# LPC18xx register map
File version: 0.23
CPU: CM3 r0p0, little endian, no MPU, no FPU, 3 interrupt priority bits
Registers are 32-bit, read-write, reset 0x0 unless marked. A register's access mark holds for its fields unless they carry their own. Offsets are from the block's base; [hi:lo] are bit positions; <NAME> marks a mode.

## ETHERNET (part 1 of 2)
Base 0x40010000
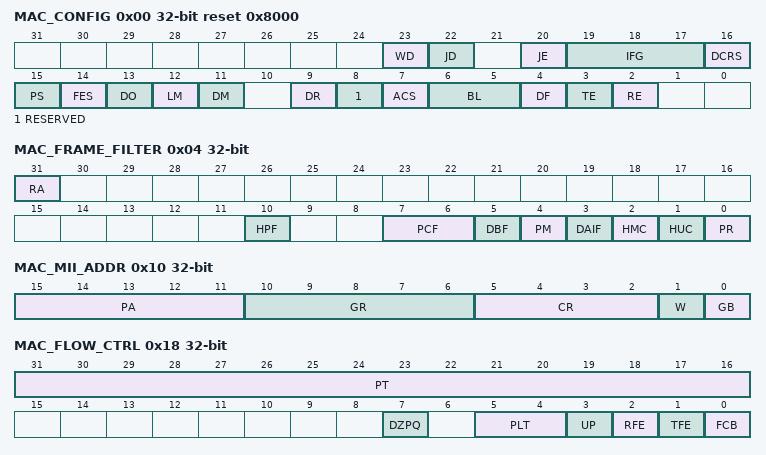
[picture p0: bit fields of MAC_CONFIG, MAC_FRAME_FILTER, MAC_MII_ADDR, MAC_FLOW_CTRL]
0x00 MAC_CONFIG reset 0x8000 — MAC configuration register
  [23] WD — Watchdog Disable When this bit is set, the MAC disables the watchdog timer on the receiver, and can receive frames of up to 16,384 bytes. When this bit is reset, the MAC allows no more than 2,048 bytes (10,240 if JE is set high) of the frame being received and cuts off any bytes received after that.
  [22] JD — Jabber Disable When this bit is set, the MAC disables the jabber timer on the transmitter, and can transfer frames of up to 16,384 bytes. When this bit is reset, the MAC cuts off the transmitter if the application sends out more than 2,048 bytes of data (10,240 if JE is set high) during transmission.
  [20] JE — Jumbo Frame Enable When this bit is set, MAC allows Jumbo frames of 9,018 bytes (9,022 bytes for VLAN tagged frames) without reporting a giant frame error in the receive frame status.
  [19:17] IFG — Inter-frame gap These bits control the minimum IFG between frames during transmission. 000 = 96 bit times 001 = 88 bit times 010 = 80 bit times ... 000 = 40 bit times Note that in Half-Duplex mode, the minimum IFG can be configured for 64 bit times (IFG = 100) only. Lower values are not considered
  [16] DCRS — Disable carrier sense during transmission When set high, this bit makes the MAC transmitter ignore the MII CRS signal during frame transmission in Half-Duplex mode. This request results in no errors generated due to Loss of Carrier or No Carrier during such transmission. When this bit is low, the MAC transmitter generates such errors due to Carrier Sense and will even abort the transmissions.
  [15] PS — Port select 1 = MII (100 Mbp) - this is the only allowed value.
  [14] FES — Speed Indicates the speed in Fast Ethernet (MII) mode: 0 = 10 Mbps 1 = 100 Mbps
  [13] DO — Disable Receive Own When this bit is set, the MAC disables the reception of frames in Half-Duplex mode. When this bit is reset, the MAC receives all packets that are given by the PHY while transmitting. This bit is not applicable if the MAC is operating in Full-Duplex mode.
  [12] LM — Loopback Mode When this bit is set, the MAC operates in loopback mode at MII. The MII Receive clock input is required for the loopback to work properly, as the Transmit clock is not looped-back internally.
  [11] DM — Duplex Mode When this bit is set, the MAC operates in a Full-Duplex mode where it can transmit and receive simultaneously.
  [9] DR — Disable Retry When this bit is set, the MAC will attempt only 1 transmission. When a collision occurs on the MII, the MAC will ignore the current frame transmission and report a Frame Abort with excessive collision error in the transmit frame status. When this bit is reset, the MAC will attempt retries based on the settings of BL. This bit is applicable only to Half-Duplex mode and is reserved (RO with default value) in Full- Duplex-only configuration.
  [8] RESERVED — Link Up/Down Indicates whether the link is up or down during the transmission of configuration in SMII interface: 0 = Link down 1 = Link up
  [7] ACS — Automatic Pad/CRC Stripping When this bit is set, the MAC strips the Pad/FCS field on incoming frames only if the length's field value is less than or equal to 1,500 bytes. All received frames with length field greater than or equal to 1,501 bytes are passed to the application without stripping the Pad/FCS field. When this bit is reset, the MAC will pass all incoming frames to the Host unmodified.
  [6:5] BL — Back-Off Limit The Back-Off limit determines the random integer number (r) of slot time delays (4,096 bit times for 1000 Mbps and 512 bit times for 10/100 Mbps) the MAC waits before rescheduling a transmission attempt during retries after a collision. This bit is applicable only to Half-Duplex mode and is reserved (RO) in Full-Duplex-only configuration. 00: k = min (n, 10) 01: k = min (n, 8) 10: k = min (n, 4) 11: k = min (n, 1) where n = retransmission attempt. The random integer r takes the value in the range 0 <= r <= 2k.
  [4] DF — Deferral Check When this bit is set, the deferral check function is enabled in the MAC. The MAC will issue a Frame Abort status, along with the excessive deferral error bit set in the transmit frame status when the transmit state machine is deferred for more than 24,288 bit times in 10/100-Mbps mode. If the Core is configured for 1000 Mbps operation, or if the Jumbo frame mode is enabled in 10/100-Mbps mode, the threshold for deferral is 155,680 bits times. Deferral begins when the transmitter is ready to transmit, but is prevented because of an active CRS (carrier sense) signal on the MII. Defer time is not cumulative. If the transmitter defers for 10,000 bit times, then transmits, collides, backs off, and then has to defer again after completion of back-off, the deferral timer resets to 0 and restarts. When this bit is reset, the deferral check function is disabled and the MAC defers until the CRS signal goes inactive. This bit is applicable only in Half-Duplex mode and is reserved (RO) in Full-Duplex-only configuration.
  [3] TE — Transmitter Enable When this bit is set, the transmit state machine of the MAC is enabled for transmission on the MII. When this bit is reset, the MAC transmit state machine is disabled after the completion of the transmission of the current frame, and will not transmit any further frames.
  [2] RE — Receiver enable When this bit is set, the receiver state machine of the MAC is enabled for receiving frames from the MII. When this bit is reset, the MAC receive state machine is disabled after the completion of the reception of the current frame, and will not receive any further frames from the MII.
0x04 MAC_FRAME_FILTER
  [31] RA — Receive all When this bit is set, the MAC Receiver module passes to the Application all frames received irrespective of whether they pass the address filter. The result of the SA/DA filtering is updated (pass or fail) in the corresponding bits in the Receive Status Word. When this bit is reset, the Receiver module passes to the Application only those frames that pass the SA/DA address filter.
  [10] HPF — Hash or perfect filter When set, this bit configures the address filter to pass a frame if it matches either the perfect filtering or the hash filtering as set by HMC or HUC bits. When low and if the HUC/HMC bit is set, the frame is passed only if it matches the Hash filter.
  [7:6] PCF — Pass Control Frames These bits control the forwarding of all control frames (including unicast and multicast PAUSE frames). Note that the processing of PAUSE control frames depends only on RFE of the Flow Control Register. 00 = MAC filters all control frames from reaching the application. 01 = MAC forwards all control frames except PAUSE control frames to application even if they fail the Address filter. 10 = MAC forwards all control frames to application even if they fail the Address Filter. 11 = MAC forwards control frames that pass the Address Filter.
  [5] DBF — Disable Broadcast Frames When this bit is set, the AFM module filters all incoming broadcast frames. When this bit is reset, the AFM module passes all received broadcast frames.
  [4] PM — Pass All Multicast When set, this bit indicates that all received frames with a multicast destination address (first bit in the destination address field is '1') are passed. When reset, filtering of multicast frame depends on HMC bit.
  [3] DAIF — DA Inverse Filtering When this bit is set, the Address Check block operates in inverse filtering mode for the DA address comparison for both unicast and multicast frames. When reset, normal filtering of frames is performed.
  [2] HMC — Hash Multicast When set, MAC performs destination address filtering of received multicast frames according to the hash table. When reset, the MAC performs a perfect destination address filtering for multicast frames, that is, it compares the DA field with the values programmed in DA registers.
  [1] HUC — Hash Unicast When set, MAC performs destination address filtering of unicast frames according to the hash table. When reset, the MAC performs a perfect destination address filtering for unicast frames, that is, it compares the DA field with the values programmed in DA registers.
  [0] PR — Promiscuous Mode When this bit is set, the Address Filter module passes all incoming frames regardless of its destination or source address. The SA/DA Filter Fails status bits of the Receive Status Word will always be cleared when PR is set.
0x08 MAC_HASHTABLE_HIGH — Hash table high register
  [31:0] HTH — Hash table high This field contains the upper 32 bits of Hash table.
0x0C MAC_HASHTABLE_LOW — Hash table low register
  [31:0] HTL — Hash table low This field contains the upper 32 bits of Hash table.
0x10 MAC_MII_ADDR — MII address register
  [15:11] PA — Physical layer address This field tells which of the 32 possible PHY devices are being accessed.
  [10:6] GR — MII register These bits select the desired MII register in the selected PHY device.
  [5:2] CR — CSR clock range The CSR Clock Range selection determines the frequency of the MDC clock. The suggested range of CLK_M3_ETHERNET frequency applicable for each value below (when Bit[5] = 0) ensures that the MDC clock is approximately between the frequency range 1.0 MHz - 2.5 MHz. When bit 5 is set, you can achieve MDC clock of frequency higher than the IEEE 802.3 specified frequency limit of 2.5 MHz and program a clock divider of lower value. For example, when CLK_M3_ETHERNET is of frequency 100 MHz and you program these bits as 1010, then the resultant MDC clock will be of 12.5 MHz which is outside the limit of IEEE 802.3 specified range. Program the values given below only if the interfacing chips supports faster MDC clocks. See Table 554 for bit values.
  [1] W — MII write When set, this bit tells the PHY that this will be a Write operation using the MII Data register. If this bit is not set, this will be a Read operation, placing the data in the MII Data register.
  [0] GB — MII busy This register field can be read by the application (Read), can be set to 1 by the application with a register write of 1 (Write Set), and is cleared to 0 by the core (Self Clear). The application cannot clear this type of field, and a register write of 0 to this bit has no effect on this field. This bit should read a logic 0 before writing to this register and the MAC_MII_DATA register. This bit must also be set to 0 during a Write to this register. During a PHY register access, this bit will be set to 1 by the Application to indicate that a Read or Write access is in progress. The MAC_MII_DATA register should be kept valid until this bit is cleared by the MAC during a PHY Write operation. The MAC_MII_DATA register is invalid until this bit is cleared by the MAC during a PHY Read operation. This register should not be written to until this bit is cleared.
0x14 MAC_MII_DATA — MII data register
  [15:0] GD — MII data This contains the 16-bit data value read from the PHY after a Management Read operation or the 16-bit data value to be written to the PHY before a Management Write operation.
0x18 MAC_FLOW_CTRL — Flow control register
  [31:16] PT — Pause time This field holds the value to be used in the Pause Time field in the transmit control frame. If the Pause Time bits is configured to be double-synchronized to the MII clock domain, then consecutive writes to this register should be performed only after at least 4 clock cycles in the destination clock domain.
  [7] DZPQ — Disable Zero-Quanta Pause When set, this bit disables the automatic generation of Zero-Quanta Pause Control frames on the deassertion of the flow-control signal from the FIFO layer. When this bit is reset, normal operation with automatic Zero-Quanta Pause Control frame generation is enabled.
  [5:4] PLT — Pause Low Threshold This field configures the threshold of the PAUSE timer at which the input flow control is checked for automatic retransmission of PAUSE Frame. The threshold values should be always less than the Pause Time configured in Bits[31:16]. For example, if PT = 0x100 (256 slot-times), and PLT = 01, then a second PAUSE frame is automatically transmitted if the flow control signal is asserted at 228 (256 - 28) slot-times after the first PAUSE frame is transmitted.
  [3] UP — Unicast Pause Frame Detect When this bit is set, the MAC will detect the Pause frames with the station's unicast address specified in MAC Address0 High Register and MAC Address0 Low Register, in addition to the detecting Pause frames with the unique multicast address. When this bit is reset, the MAC will detect only a Pause frame with the unique multicast address specified in the 802.3x standard.
  [2] RFE — Receive Flow Control Enable When this bit is set, the MAC will decode the received Pause frame and disable its transmitter for a specified (Pause Time) time. When this bit is reset, the decode function of the Pause frame is disabled.
  [1] TFE — Transmit Flow Control Enable In Full-Duplex mode, when this bit is set, the MAC enables the flow control operation to transmit Pause frames. When this bit is reset, the flow control operation in the MAC is disabled, and the MAC will not transmit any Pause frames. In Half-Duplex mode, when this bit is set, the MAC enables the back-pressure operation. When this bit is reset, the backpressure feature is disabled.
  [0] FCB — Flow Control Busy/Backpressure Activate This register field can be read by the application (Read), can be set to 1 by the application with a register write of 1 (Write Set), and is cleared to 0 by the core (Self Clear). The application cannot clear this type of field, and a register write of 0 to this bit has no effect on this field. This bit initiates a Pause Control frame in Full-Duplex mode. In Full-Duplex mode, this bit should be read as 0 before writing to the Flow Control register. To initiate a Pause control frame, the Application must set this bit to 1. During a transfer of the Control Frame, this bit will continue to be set to signify that a frame transmission is in progress. After the completion of Pause control frame transmission, the MAC will reset this bit to 0. The Flow Control register should not be written to until this bit is cleared. In Half-Duplex mode, when this bit is set (and TFE is set), then backpressure is asserted by the MAC Core. During backpressure, when the MAC receives a new frame, the transmitter starts sending a JAM pattern resulting in a collision. This control register bit is logically ORed with the flow controller input signal for the backpressure function. When the MAC is configured to Full- Duplex mode, the BPA is automatically disabled.
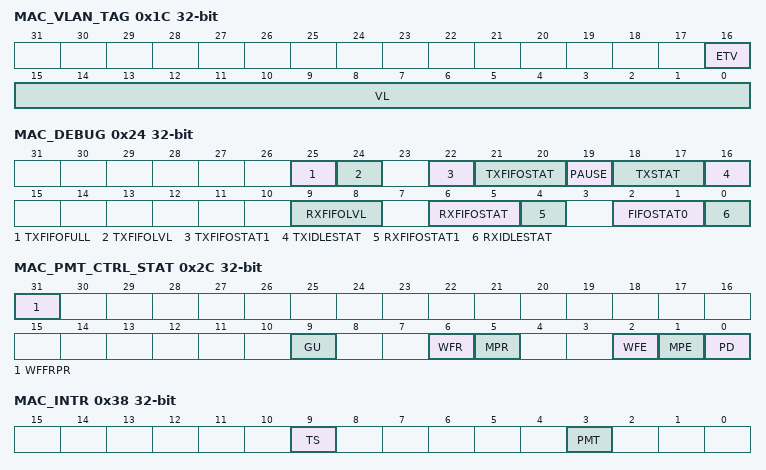
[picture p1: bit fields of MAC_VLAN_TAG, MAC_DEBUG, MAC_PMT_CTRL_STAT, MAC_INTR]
0x1C MAC_VLAN_TAG — VLAN tag register
  [16] ETV — Enable 12-Bit VLAN Tag Comparison When this bit is set, a 12-bit VLAN identifier, rather than the complete 16-bit VLAN tag, is used for comparison and filtering. Bits[11:0] of the VLAN tag are compared with the corresponding field in the received VLAN-tagged frame. When this bit is reset, all 16 bits of the received VLAN frame's fifteenth and sixteenth bytes are used for comparison.
  [15:0] VL — VLAN Tag Identifier for Receive Frames This contains the 802.1Q VLAN tag to identify VLAN frames, and is compared to the fifteenth and sixteenth bytes of the frames being received for VLAN frames. Bits[15:13] are the User Priority, Bit[12] is the Canonical Format Indicator (CFI) and bits[11:0] are the VLAN tag's VLAN Identifier (VID) field. When the ETV bit is set, only the VID (Bits[11:0]) is used for comparison. If VL (VL[11:0] if ETV is set) is all zeros, the MAC does not check the fifteenth and sixteenth bytes for VLAN tag comparison, and declares all frames with a Type field value of 0x8100 to be VLAN frames.
0x24 MAC_DEBUG ro — Debug register
  [25] TXFIFOFULL — When high, it indicates that the TxStatus FIFO is full and hence the controller will not be accepting any more frames for transmission.
  [24] TXFIFOLVL — When high, it indicates that the TxFIFO is not empty and has some data left for transmission.
  [22] TXFIFOSTAT1 — When high, it indicates that the TxFIFO Write Controller is active and transferring data to the TxFIFO.
  [21:20] TXFIFOSTAT — State of the TxFIFO read Controller 00 = idle state 01 = READ state (transferring data to MAC transmitter) 10 = Waiting for TxStatus from MAC transmitter 11 = Writing the received TxStatus or flushing the TxFIFO
  [19] PAUSE — When high, it indicates that the MAC transmitter is in PAUSE condition (in full-duplex only) and hence will not schedule any frame for transmission.
  [18:17] TXSTAT — State of the MAC Transmit Frame Controller module: 00 = idle 01 = Waiting for Status of previous frame or IFG/backoff period to be over 10 = Generating and transmitting a PAUSE control frame (in full duplex mode) 11 = Transferring input frame for transmission
  [16] TXIDLESTAT — When high, it indicates that the MAC MII transmit protocol engine is actively transmitting data and not in IDLE state.
  [9:8] RXFIFOLVL — Status of the RxFIFO Fill-level 00 = RxFIFO Empty 01 = RxFIFO fill-level below flow-control de-activate threshold 10 = RxFIFO fill-level above flow-control activate threshold 11 = RxFIFO Full
  [6:5] RXFIFOSTAT — State of the RxFIFO read Controller: 00 = idle state 01 = reading frame data 10 = reading frame status (or Time stamp) 11 = flushing the frame data and status
  [4] RXFIFOSTAT1 — When high, it indicates that the MTL RxFIFO Write Controller is active and transferring a received frame to the FIFO.
  [2:1] FIFOSTAT0 — When high, it indicates the active state of the small FIFO Read and Write controllers respectively of the MAC receive Frame Controller module.
  [0] RXIDLESTAT — When high, it indicates that the MAC MII receive protocol engine is actively receiving data and not in IDLE state.
0x28 MAC_RWAKE_FRFLT — Remote wake-up frame filter
  [31:0] ADDR — WKUPFMFILTER address
0x2C MAC_PMT_CTRL_STAT — PMT control and status
  [31] WFFRPR — Wake-up Frame Filter Register Pointer Reset This register field can be read by the application (Read), can be set to 1 by the application with a register write of 1 (Write Set), and is cleared to 0 by the core (Self Clear). The application cannot clear this type of field, and a register write of 0 to this bit has no effect on this field. When set, resets the Remote Wake-up Frame Filter register pointer to 000. It is automatically cleared after 1 clock cycle.
  [9] GU — Global Unicast When set, enables any unicast packet filtered by the MAC (DAF) address recognition to be a wake-up frame.
  [6] WFR — Wake-up Frame Received This register field can be read by the application (Read), can be set to 1 by the Ethernet core on a certain internal event (Self Set), and is automatically cleared to 0 on a register read. A register write of 0 has no effect on this field. When set, this bit indicates the power management event was generated due to reception of a wake-up frame. This bit is cleared by a Read into this register.
  [5] MPR — Magic Packet Received This register field can be read by the application (Read), can be set to 1 by the Ethernet core on a certain internal event (Self Set), and is automatically cleared to 0 on a register read. A register write of 0 has no effect on this field. When set, this bit indicates the power management event was generated by the reception of a Magic Packet. This bit is cleared by a Read into this register.
  [2] WFE — Wake-up frame enable When set, enables generation of a power management event due to wake-up frame reception.
  [1] MPE — Magic packet enable When set, enables generation of a power management event due to Magic Packet reception.
  [0] PD — Power-down This register field can be read by the application (Read), can be set to 1 by the application with a register write of 1 (Write Set), and is cleared to 0 by the core (Self Clear). The application cannot clear this type of field, and a register write of 0 to this bit has no effect on this field. When set, all received frames will be dropped. This bit is cleared automatically when a magic packet or Wake-Up frame is received, and Power-Down mode is disabled. Frames received after this bit is cleared are forwarded to the application.This bit must only be set when either the Magic Packet Enable or Wake- Up Frame Enable bit is set high.
0x38 MAC_INTR ro — Interrupt status register
  [9] TS — Timestamp interrupt status When Advanced Timestamp feature is enabled, this bit is set when any of the following conditions is true: - The system time value equals or exceeds the value specified in the Target Time High and Low registers - There is an overflow in the seconds register This bit is cleared on reading the byte 0 of the Timestamp Status register (Table 576). Otherwise, when default Time stamping is enabled, this bit when set indicates that the system time value equals or exceeds the value specified in the Target Time registers. In this mode, this bit is cleared after the completion of the read of this Interrupt Status Register[9]. In all other modes, this bit is reserved.
  [3] PMT — PMT Interrupt Status This bit is set whenever a Magic packet or Wake-on-LAN frame is received in Power- Down mode (See bits 5 and 6 in Table 560). This bit is cleared when both bits[6:5] are cleared because of a read operation to the PMT Control and Status register.
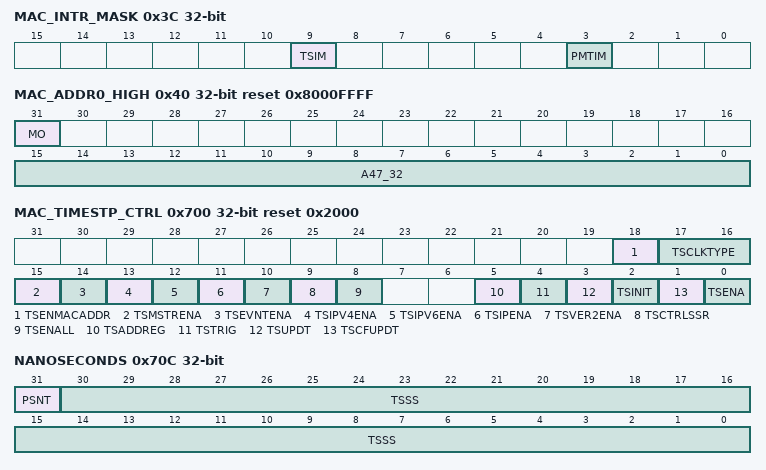
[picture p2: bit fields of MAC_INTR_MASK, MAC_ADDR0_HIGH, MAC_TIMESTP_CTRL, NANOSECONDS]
0x3C MAC_INTR_MASK — Interrupt mask register
  [9] TSIM — Timestamp interrupt mask When set, this bit disables the assertion of the interrupt signal because of the setting of Timestamp Interrupt Status bit in Table 561
  [3] PMTIM — PMT Interrupt Mask This bit when set, will disable the assertion of the interrupt signal due to the setting of PMT Interrupt Status bit in Table 561.
0x40 MAC_ADDR0_HIGH reset 0x8000FFFF — MAC address 0 high register
  [31] MO — Always 1
  [15:0] A47_32 — MAC Address0 [47:32] This field contains the upper 16 bits (47:32) of the 6-byte first MAC address. This is used by the MAC for filtering for received frames and for inserting the MAC address in the Transmit Flow Control (PAUSE) Frames.
0x44 MAC_ADDR0_LOW reset 0xFFFFFFFF — MAC address 0 low register
  [31:0] A31_0 — MAC Address0 [31:0] This field contains the lower 32 bits of the 6-byte first MAC address. This is used by the MAC for filtering for received frames and for inserting the MAC address in the Transmit Flow Control (PAUSE) Frames.
0x700 MAC_TIMESTP_CTRL reset 0x2000 — Time stamp control register
  [18] TSENMACADDR — Enable MAC address for PTP frame filtering When set, uses the DA MAC address (that matches any MAC Address register except the default MAC address 0) to filter the PTP frames when PTP is sent directly over Ethernet.
  [17:16] TSCLKTYPE — Select the type of clock node The following are the options to select the type of clock node: 00 = ordinary clock 01 = boundary clock 10 = end-to-end transparent clock 11 = peer-to-peer transparent clock
  [15] TSMSTRENA — Enable Snapshot for Messages Relevant to Master When set, the snapshot is taken for messages relevant to master node only else snapshot is taken for messages relevant to slave node. This is valid only for ordinary clock and boundary clock node.
  [14] TSEVNTENA — Enable Time stamp Snapshot for Event Messages When set, the Time stamp snapshot is taken for event messages only. When reset snapshot is taken for all other messages except Announce, Management and Signaling.
  [13] TSIPV4ENA — Enable Time stamp Snapshot for IPv4 frames When set, the Time stamp snapshot is taken for IPv4 frames.
  [12] TSIPV6ENA — Enable Time stamp Snapshot for IPv6 frames When set, the Time stamp snapshot is taken for IPv6 frames.
  [11] TSIPENA — Enable Time stamp Snapshot for PTP over Ethernet frames When set, the Time stamp snapshot is taken for frames which have PTP messages in Ethernet frames (PTP over Ethernet) also. By default snapshots are taken for UDP-IP-Ethernet PTP packets.
  [10] TSVER2ENA — Enable PTP packet snooping for version 2 format When set, the PTP packets are snooped using the 1588 version 2 format else snooped using the version 1 format.
  [9] TSCTRLSSR — Time stamp Digital or Binary rollover control When set, the Time stamp Low register rolls over after 0x3B9A_C9FF value (i.e., 1 nanosecond accuracy) and increments the Time stamp (High) seconds. When reset, the rollover value of sub-second register is 0x7FFF_FFFF. The sub-second increment has to be programmed correctly depending on the PTP reference clock frequency and this bit value.
  [8] TSENALL — Enable Time stamp for All Frames When set, the Time stamp snapshot is enabled for all frames received by the core.
  [5] TSADDREG — Addend Reg Update When set, the contents of the Time stamp Addend register is updated in the PTP block for fine correction. This is cleared when the update is completed. This register bit should be zero before setting it. This is a reserved bit when only coarse correction option is selected.
  [4] TSTRIG — Time stamp Interrupt Trigger Enable This register field can be read and written by the application (Read and Write), and is cleared to 0 by the Ethernet core (Self Clear). When set, the Time stamp interrupt is generated when the System Time becomes greater than the value written in Target Time register. This bit is reset after the generation of Time stamp Trigger Interrupt.
  [3] TSUPDT — Time stamp Update This register field can be read and written by the application (Read and Write), and is cleared to 0 by the Ethernet core (Self Clear). When set, the system time is updated (added/subtracted) with the value specified in the Time stamp High Update and Time stamp Low Update registers. This register bit should be read zero before updating it. This bit is reset once the update is completed in hardware.
  [2] TSINIT — Time stamp Initialize This register field can be read and written by the application (Read and Write), and is cleared to 0 by the Ethernet core (Self Clear). When set, the system time is initialized (over-written) with the value specified in the Time stamp High Update and Time stamp Low Update registers. This register bit should be read zero before updating it. This bit is reset once the initialize is complete.
  [1] TSCFUPDT — Time stamp Fine or Coarse Update When set, indicates that the system times update to be done using fine update method. When reset it indicates the system time stamp update to be done using Coarse method. This bit is reserved if the fine correction option is not enabled.
  [0] TSENA — Time stamp Enable When this bit, is set the timestamping is enabled for transmit and receive frames. When disabled timestamp is not added for transmit and receive frames and the TimeStamp Generator is also suspended. User has to always initialize the TimeStamp (system time) after enabling this mode.
0x704 SUBSECOND_INCR — Sub-second increment register
  [7:0] SSINC — Sub-second increment value. The value programmed in this register is accumulated with the contents of the sub-second register. For example, to achieve an accuracy of 20 ns, the value to be programmed is 20. (Program 0x14 with a 50 MHz reference clock if 1 ns accuracy is selected.)
0x708 SECONDS ro — System time seconds register
  [31:0] TSS — Time stamp second The value in this field indicates the current value in seconds of the System Time maintained by the core.
0x70C NANOSECONDS ro — System time nanoseconds register
  [31] PSNT — Positive or negative time This bit indicates positive or negative time value. If the bit is reset, it indicates that the time representation is positive, and if it is set, it indicates negative time value. (This bit represents the 32nd bit of the nanoseconds value when the Advance Time stamp feature is enabled).
  [30:0] TSSS — Time stamp sub seconds The value in this field has the sub second representation of time, with an accuracy of 0.46 nano-second. (When TSCTRLSSR in the MAC_TIMESTAMP_CTRL register is set, each bit represents 1 ns and the maximum value will be 0x3B9A_C9FF, after which it rolls-over to zero).
